# cslr_vlcd_001 register map
Vendor: Texas Instruments
Peripheral module from a debugger description file.
Registers are 16-bit, access not given, reset 0x0 unless marked. A register's access mark holds for its fields unless they carry their own. Offsets are as the file gives them; lines under a group give offsets from that group; [hi:lo] are bit positions; {n}, {i} and the like mark numbered series; 'fields as' and 'values as' point back to an identical list; <NAME> marks a mode.

## VLCD — DaVinci - VLCD Control Registers
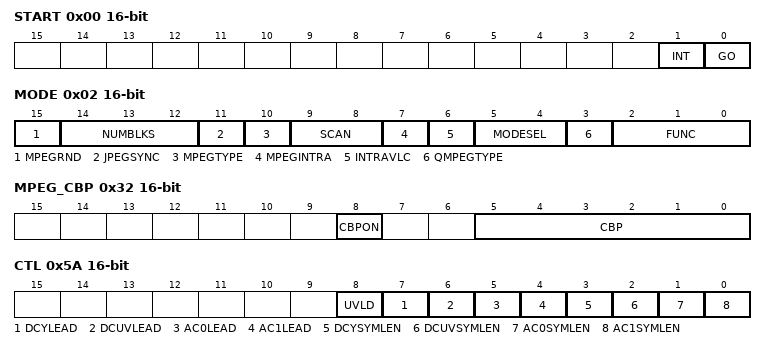
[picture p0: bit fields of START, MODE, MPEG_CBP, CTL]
0x00 START — VLCD Start Register
  [1] INT rw — VLCD to DSP Interrupt
    0=DISABLE (Disable interrupt); 1=ENABLE (Enable interrupt)
  [0] GO rw — \hVLCD Go. Write: 0: Not used (do not write 0). 1: Start VLCD module. Read: 0: Idle. 1: Busy . Writing '1' starts the VLCD module. Reading provides VLCD execution status.
0x02 MODE rw — VLCD Mode Register
  [15] MPEGRND — Round control for MPEG_INVQ
    0=OFF (round off); 1=ON (round on)
  [14:12] NUMBLKS — \hSpecify number of 8x8 blocks to process. Number of blocks can be 1 through 6.
  [11] JPEGSYNC — \hJPEG Sync Insertion . Writing '1' enables inserting 00 byte after FF byte
    0=OFF; 1=ON
  [10] MPEGTYPE — MPEG Picture Coding Type
    0=I_P_B_PICTURE (I,P,B picture coding); 1=D_PICTURE (D picture coding)
  [9:8] SCAN — Scan Mode (VLC/VLD)
    0=LINEARSCAN; 1=ZIGZAGSCAN; 2=ALTERNATE_VERTICALSCAN; 3=ALTERNATE_HORIZONTALSCAN
  [7] MPEGINTRA — \hIntra Macro Block Select . Selects whether blocks are encoded as Intra Macro blocks
    0=NON_INTRAMB (Non-intra macro block); 1=INTRAMB (Intra macro block (Set to '1' in JPEG mode))
  [6] INTRAVLC — MPEG Intra VLC Format
  [5:4] MODESEL — Codec Mode Select
    0=JPEG; 1=MPEG1; 2=MPEG4; 3=H263
  [3] QMPEGTYPE — Quantization type for Encode and Decode in MPEG4
    0=TYPE0; 1=TYPE1
  [2:0] FUNC — Function Select
    0=Q; 1=IQ; 2=VLC; 3=VLD; 4=Q_IQ; 5=Q_VLC; 6=Q_IQ_VLC; 7=VLD_IQ
0x04 QIN_ADDR — Quantization Input Address Register
  [11:0] ADDR rw — Start address of input data used for Quantization
0x06 QOUT_ADDR — Quantization Output Address Register
  [11:0] ADDR rw — Start address of output data used for Quantization
0x08 IQIN_ADDR — Inverse Quantization Input Address Register
  [11:0] ADDR rw — Start address of input data used for inverse quantization
0x0A IQOUT_ADDR — Inverse Quantization Output Address Register
  [11:0] ADDR rw — Start address of output data used for inverse quantization
0x0C VLCDIN_ADDR — VLCD Input Address
  [11:0] ADDR rw — Start address of input data used for VLC/VLD
0x0E VLCDOUT_ADDR — VLCD Output Address
  [11:0] ADDR rw — \hStart address of output data used for VLC/VLD . When VLD, the address should be 32bit aligned.
{0x10+2i} DC_PRED{i} (i=0..4) — Quantization DC Predictor {i} Register
  [11:0] PRED{i} rw — Initial/final DC predictors for quantization
0x1A DC_PRED5 — Quantization DC Predoctor 4 Register
  [11:0] PRED5 rw — Initial/final DC predictors for quantization
{0x1C+2i} IDC_PRED{i} (i=0..4) — Inverse Quantization DC Predictor {i} Register
  [11:0] IPRED{i} rw — Initial/final DC predictors for inverse quantization
0x26 IDC_PRED5 — Inverse Quantization DC Predoctor 4 Register
  [11:0] IPRED5 rw — Initial/final DC predictors for inverse quantization
0x28 MPEG_INVQ rw — MPEG Inverse Quantization Scale Register
  [15:0] MPEG_INVQ — 2^15/quant_scale for MPEG quantization
0x2A MPEG_Q — MPEG Quantization Scale Register
  [7:0] MQ rw — quant_scale for MPEG de-quantization
0x2C MPEG_DELTA_Q — MPEG Quantization Delta Register
  [8:0] MDELQ rw — Number of delta value for use in MPEG quantization (2's compliment)
0x2E MPEG_DELTA_IQ — MPEG Inverse Quantization Delta Register
  [8:0] MDELIQ rw — Number of delta value for use in MPEG inverse quantization (2's compliment)
0x30 MPEG_THRED
  [11:0] MTHRED rw — Number of threds value for use in MPEG Quantization
0x32 MPEG_CBP — MPEG coded Block Pattern Register
  [8] CBPON rw — \hCBP Detection Control
    0=CBP_DETECT_OFF (CBP detect off (JPEG)); 1=CBP_DETECT_ON
  [5:0] CBP rw — \hCoded block pattern. Indicates at least one nonzero in a block. For the standard six block macro block, CBP of the first block would be in bit position five. The second block's CBP bit in position 4, down to the last block being in bit position 0.
0x34 LUMA_VECTOR — LUMA Bit Vector Register
  [5:0] LUMVECT rw — \hLuma Bit Vector. Setting this bit high indicates that block has luminance data. For the standard six block macro block, the first block's Luma bit would be in bit position five. The second block's coded bit in position 4, down to the last block being in bit position 0.
0x36 HUFFTAB_DCY — Huffman DC Y Table Base Address Register
  [10:0] HDCY rw — \hBase address for Huffman DC Y tables. Should be even (32-bit aligned).
0x38 HUFFTAB_DCUV — Huffman DC UV Table Base Address Register
  [10:0] HDCUV rw — \hBase address for Huffman DC UV tables. Should be even (32-bit aligned).
0x3A HUFFTAB_AC0 — Huffman AC0 Table Base Address Register
  [10:0] HAC0 rw — \hBase address for Huffman AC0 tables. Should be even (32-bit aligned).
0x3C HUFFTAB_AC1 — Huffman AC1 Table Base Address Register
  [10:0] HAC1 rw — \hBase address for Huffman AC1 tables. Should be even (32-bit aligned).
0x3E OFLEV_MAXOTAB — MPEG Max 0 Level Table Base Address Register
  [10:0] MAX0 rw — \hBase address for MPEG max 0 level tables. Should be even (32-bit aligned).
0x40 OFLEV_MAX1TAB — MPEG Max 1 Level Table Base Address Register
  [10:0] MAX1 rw — \hBase address for MPEG max 1 level tables. Should be even (32-bit aligned).
0x42 CTLTAB_DCY — DC Y Control Lookup Table Base Address Register
  [10:0] CDCY rw — \hControl Table DC Y pointer. Address pointer to the starting word of the Control Table DC Y lookup table in VLCD Huffman memory used by the UVLD. This table shall start on a 32 bit word boundary.
0x44 CTLTAB_DCUV — DC UV Control Lookup Table Base Address Register
  [10:0] CDCUV rw — \hControl Table DC UV pointer. Address pointer to the starting word of the Control Table DC UV lookup table in VLCD Huffman memory used by the UVLD. This table shall start on a 32 bit word boundary.
0x46 CTLTAB_AC0 — AC0 Control Lookup Table Base Address Register
  [10:0] CAC0 rw — \hControl Table DC AC0 pointer. Address pointer to the starting word of the Control Table DC AC0 lookup table in VLCD Huffman memory used by the UVLD. This table shall start on a 32 bit word boundary.
0x48 CTLTAB_AC1 — AC1 Control Lookup Table Base Address Register
  [10:0] CAC1 rw — \hControl Table DC AC1 pointer. Address pointer to the starting word of the Control Table DC AC1 lookup table in VLCD Huffman memory used by the UVLD. This table shall start on a 32 bit word boundary.
0x4A OFFSET_DCY — DC Y Symbol Lookup Table Address Offset Register
  [10:0] ODCY rw — \hSymbol Table DC Y offset. Used to address the Symbol Table DC Y lookup table. The purpose of this offset is to avoid negative numbers being used in the Control table.
0x4C OFFSET_DCUV — DC UV Symbol Lookup Table Address Offset Register
  [10:0] ODCUV rw — \hSymbol Table DC UV offset. Used to address the Symbol Table DC UV lookup table. The purpose of this offset is to avoid negative numbers being used in the Control table.
0x4E OFFSET_AC0 — AC0 Symbol Lookup Table Address Offset Register
  [10:0] OAC0 rw — \hSymbol Table AC0 offset. Used to address the Symbol Table AC0 lookup table. The purpose of this offset is to avoid negative numbers being used in the Control table.
0x50 OFFSET_AC1 — AC1 Symbol Lookup Table Address Offset Register
  [10:0] OAC1 rw — \hSymbol Table AC1 offset. Used to address the Symbol Table AC1 lookup table. The purpose of this offset is to avoid negative numbers being used in the Control table.
0x52 SYMTAB_DCY — DC Y Symbol Lookup Table Base Address Register
  [10:0] SDCY rw — \hSymbol Table DC Y pointer. Address pointer to the starting word of the Symbol Table DC Y lookup table in VLCD Huffman memory used by the UVLD. This table shall start on a 32 bit word boundary.
0x54 SYMTAB_DCUV — DC UV Symbol Lookup Table Base Address Register
  [10:0] SDCUV rw — \hSymbol Table DC UV pointer. Address pointer to the starting word of the Symbol Table DC UV lookup table in VLCD Huffman memory used by the UVLD. This table shall start on a 32 bit word boundary.
0x56 SYMTAB_AC0 — AC0 Symbol Lookup Table Base Address Register
  [10:0] SAC0 rw — \hSymbol Table AC0 pointer. Address pointer to the starting word of the Symbol Table AC0 lookup table in VLCD Huffman memory used by the UVLD. This table shall start on a 32 bit word boundary.
0x58 SYMTAB_AC1 — AC1 Symbol Lookup Table Base Address Register
  [10:0] SAC1 rw — \hSymbol Table AC1 pointer. Address pointer to the starting word of the Symbol Table AC1 lookup table in VLCD Huffman memory used by the UVLD. This table shall start on a 32 bit word boundary.
0x5A CTL — VLD Control Register
  [8] UVLD rw — \hSelect UVLD algorithm
    0=VLD (Select VLD algorithm); 1=RVLC (Select RVLC algorithm)
  [7] DCYLEAD rw — \hThis bit signifies that the UVLD is expecting a 1 leading Huffman Table for the DC Y Tables
  [6] DCUVLEAD rw — \hThis bit signifies that the UVLD is expecting a 1 leading Huffman Table for the DC UV Tables
  [5] AC0LEAD rw — \hThis bit signifies that the UVLD is expecting a 1 leading Huffman Table for the AC 0 Tables
  [4] AC1LEAD rw — \hThis bit signifies that the UVLD is expecting a 1 leading Huffman Table for the AC 1 Tables
  [3] DCYSYMLEN rw — \hDC Y Symbol Length. Bit length of the decoded symbol in the DC Y Symbol Table.
    0=12BITSYM (12 bit symbol length); 1=11BITSYM (11 bit symbol length)
  [2] DCUVSYMLEN rw — \hDC UV Symbol Length. Bit length of the decoded symbol in the DC UV Symbol Table.
    values as DCYSYMLEN
  [1] AC0SYMLEN rw — \hAC0 Symbol Length. Bit length of the decoded symbol in the AC 0 Symbol Table.
    values as DCYSYMLEN
  [0] AC1SYMLEN rw — \hAC1 Symbol Length. Bit length of the decoded symbol in the AC 1 Symbol Table.
    values as DCYSYMLEN
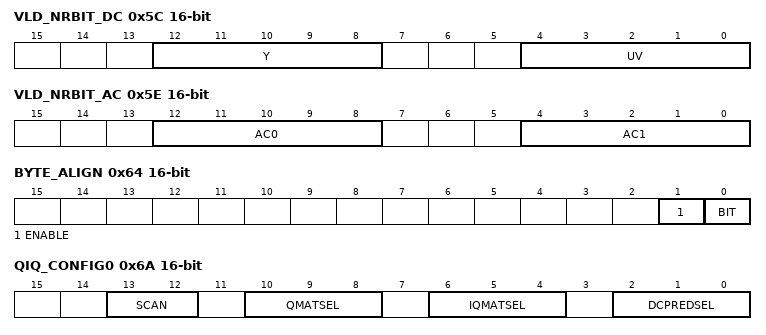
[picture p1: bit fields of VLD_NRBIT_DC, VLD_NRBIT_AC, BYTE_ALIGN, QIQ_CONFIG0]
0x5C VLD_NRBIT_DC — DC Number of Bits Register
  [12:8] Y rw — Number of bits to test for the DC Y term as input to the UVLD
  [4:0] UV rw — Number of bits to test for the DC UV term as input to the UVLD
0x5E VLD_NRBIT_AC — AC Number of Bits Register
  [12:8] AC0 rw — Number of bits to test for the AC0 term as input to the UVLD
  [4:0] AC1 rw — Number of bits to test for the AC1 term as input to the UVLD
0x60 BITS_BPTR — Bits Pointer Register
  [3:0] BPTR rw — \hNumber of valid bits in the 16-bit word pointed by VLCDOUT_ADDR(VLC) or VLCDIN_ADDR(VLD). Value = 0..15 example: BPTR = 5 b15 b0. BITS_WORD = VVVVV * * * * * * * * * * *
0x62 BITS_WORD rw
  [15:0] BITS_WORD — Last Bitstream at VLCDOUT_ADDR(VLC) or VLCDIN_ADDR(VLD).
0x64 BYTE_ALIGN
  [1] ENABLE rw — \hByte Align. VLC: When set to '1' , enables byte alignment in current processing macro block. VLD: When set to '1' , it means current processing bistream is byte aligned.
  [0] BIT rw — \hByte Align Fill value. VLC: When byte align is selected, last byte is filled with this bit. VLD: No meaning
0x66 HEAD_ADDR — Header Address Register
  [10:0] HDADDR rw — \hHeader Base. Base address for header data to be inserted. Should be even (32-bit aligned).
0x68 HEAD_NUM — Number of Header Data Register
  [9:0] HDNUM rw — \hNumber of header data to be inserted(1-1023).
0x6A QIQ_CONFIG0 — QIQ Configuration Register #0
  [13:12] SCAN rw — Scan Mode (VLC/VLD)
    0=LINEARSCAN; 1=ZIGZAGSCAN; 2=ALTERNATE_V_SCAN (Alternate-vertical scan); 3=ALTERNATE_H_SCAN (Alternate-horizontal scan)
  [10:8] QMATSEL rw — Quant matrix selector (1 of 8 banks)
  [6:4] IQMATSEL rw — Inverse Quantization matrix selector (1 of 8 banks)
  [2:0] DCPREDSEL rw — DC predictor selector (1 of 6)
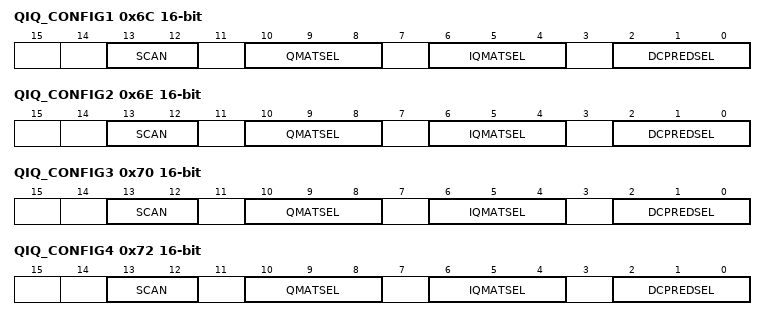
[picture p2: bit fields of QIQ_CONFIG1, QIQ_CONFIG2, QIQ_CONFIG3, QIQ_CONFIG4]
0x6C QIQ_CONFIG1 — QIQ configuration Register #1
  [13:12] SCAN rw — Scan Mode (VLC/VLD)
    0=LINEARSCAN (Alternate-vertical scan); 1=ZIGZAGSCAN (Alternate-horizontal scan); 2=ALTERNATE_V_SCAN
  [10:8] QMATSEL rw — Quant matrix selector (1 of 8 banks)
  [6:4] IQMATSEL rw — Inverse Quantization matrix selector (1 of 8 banks)
  [2:0] DCPREDSEL rw — DC predictor selector (1 of 6)
0x6E QIQ_CONFIG2 — QIQ Congiguration Register #2
  fields as QIQ_CONFIG0
0x70 QIQ_CONFIG3 — QIQ configuration Register #3
  fields as QIQ_CONFIG0
0x72 QIQ_CONFIG4 — QIQ Congiguration Register #4
  fields as QIQ_CONFIG0
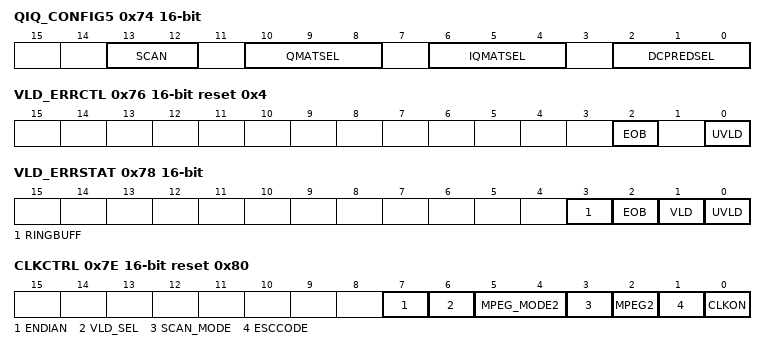
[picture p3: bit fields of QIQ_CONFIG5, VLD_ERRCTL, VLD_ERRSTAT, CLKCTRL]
0x74 QIQ_CONFIG5 — QIQ configuration Register #5
  fields as QIQ_CONFIG0
0x76 VLD_ERRCTL reset 0x4 — VLD Error Control Register
  [2] EOB rw — \hEOB Error Control . When an error occurs, stop huffman decoding. Error occurs when EOB cannot be found during VLD
    0=OFF; 1=ON
  [0] UVLD rw — \hUVLD Error Control . When an error occurs, stop huffman decoding. Error occurs when at least one out of table entry found in macro block
    0=OFF; 1=ON
0x78 VLD_ERRSTAT — VLD Error Status Register
  [3] RINGBUFF ro — \hRingbuffer over flow status. This bit shows that ring pointer reached at max address.
  [2] EOB ro — \hEOB Error
    0=NOERROR; 1=NO_EOB_IN_VLD (can't find the EOB in VLD)
  [1] VLD ro — \hVLD Error
    0=NOERROR; 1=NON_FF00_IN_MB (found at least one non-FF00 code in macro block)
  [0] UVLD ro — \hUVLD Error
    0=NOERROR; 1=OUT_OF_TABLE_ENTRY_IN_MB (found at least 1 out of table entry in macro block)
0x7A RING_START — Ring Buffer Start Address Register
  [12:0] RSTART rw — \hRing buffer start address. VLC: When output pointer reaches end address, output pointer starts at start address automatically. VLD: When input pointer reaches end address, input pointer starts at start pointer automatically.
0x7C RING_END reset 0x1FFF — Ring Buffer End Address Register
  [12:0] REND rw — \hRing buffer end address. VLC: When output pointer reaches end address, output pointer starts at start address automatically. VLD: When input pointer reaches end address, input pointer starts at start pointer automatically.
0x7E CLKCTRL reset 0x80 — VLD Prefix Register - DC
  [7] ENDIAN ro — \hEndian Control for VLD/VLC
    1=LITTLE (Fixed to little endian for DaVinci)
  [6] VLD_SEL rw — \hVLD Algorithm Selection
    0=DM270 (same as DM270); 1=MPEG4_RVLC
  [5:4] MPEG_MODE2 rw — \hAdditional MPEG-4 Mode. This register active only when MODE:MODESEL is set to MPEG-4
    0=MPEG4 (MPEG4 normal); 1=MPEG4DATAPARTITION; 2=MPEG4RVLC_D; 3=WMV9 (WMV9 decode only)
  [3] SCAN_MODE rw — \hScan Mode
    0=SEL_BY_MODE (SCAN type is selected by VLCD_MODE(9:8)); 1=SEL_BY_QIQCFG (SCAN type is selected by QIQ_CONFIG1 to 5)
  [2] MPEG2 rw — \hMPEG2 Mode Select. This register only active when MODE:MODESEL is set to MPEG1
    0=MPEG1; 1=MPEG2
  [1] ESCCODE rw — \hMPEG4 Escape Coding
    0=ESC3 (escape 3 only (DSC25)); 1=ESC1_2_AND_3 (escape 1, 2, and 3)
  [0] CLKON rw — \hDynamic Clock Control
    0=ON; 1=OFF
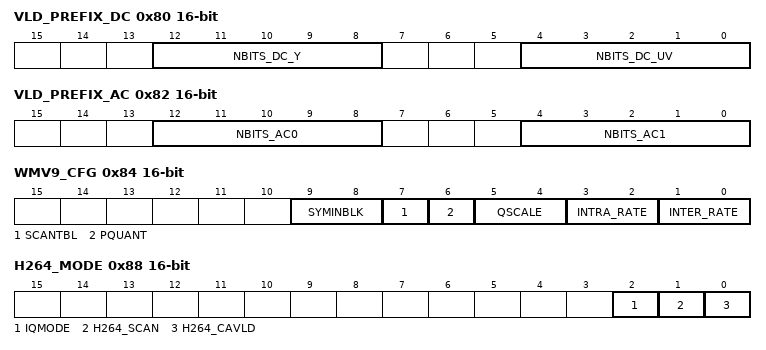
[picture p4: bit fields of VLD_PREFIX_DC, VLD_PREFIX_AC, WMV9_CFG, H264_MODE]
0x80 VLD_PREFIX_DC — VLD Prefix Register - DC
  [12:8] NBITS_DC_Y rw — \hNumber of prefix bits of control table for DC_Y term as input to UVLD
  [4:0] NBITS_DC_UV rw — \hNumber of prefix bits of control table for DC_UV term as input to UVLD
0x82 VLD_PREFIX_AC — VLD Prefix Register - AC
  [12:8] NBITS_AC0 rw — \hNumber of prefix bits of control table for AC0 term as input to UVLD
  [4:0] NBITS_AC1 rw — \hNumber of prefix bits of control table for AC1 term as input to UVLD
0x84 WMV9_CFG — WMV9 Configuration
  [9:8] SYMINBLK rw — \hNumber of symbols in a block
    0=64; 1=32; 2=16
  [7] SCANTBL rw — WMV9 Scan Table
  [6] PQUANT rw — Setting '1' specifies PQUANT>=8, I-frame andand no m_bDQuant
  [5:4] QSCALE rw — Quantization Scale
  [3:2] INTRA_RATE rw — \hIntra Frame Rate Type
    0=LOW_MO (low motion); 1=HI_MO (high motion); 2=MID_RATE; 3=HI_RATE (high rate)
  [1:0] INTER_RATE rw — \hInter Frame Rate Type
    values as INTRA_RATE
0x86 FIRST_FRAME reset not defined
  [0] FF — \hAction for first frame. Setting '1' specifies the first case of escape mode 3 in a frame. This register is cleared when found a ESCAPE3(WMV9)
0x88 H264_MODE
  [2] IQMODE rw — \hIQ Mode
    0=CHROMA (Chroma block); 1=LUMA (Luma block)
  [1] H264_SCAN rw — \hH264 Scan Table Enable
    0=OFF; 1=ON (H.264 scan table (IQ Mode))
  [0] H264_CAVLD rw — \hCAVLD Enable
    0=OFF; 1=ON (H.264 CAVLD decoding)
0x8A NRBITS_THRED reset 0x6 — First Frame
  [3:0] THRESHOLD rw — \hThreshold level of NRBITS (number of bits) in WMV9 decoding. When the NRBITS from Huffman table is greater than this threshold value, UVLD error happens. Current VLD algorithm defines the maximum NRBITS as 6. No need to modify the default value.
